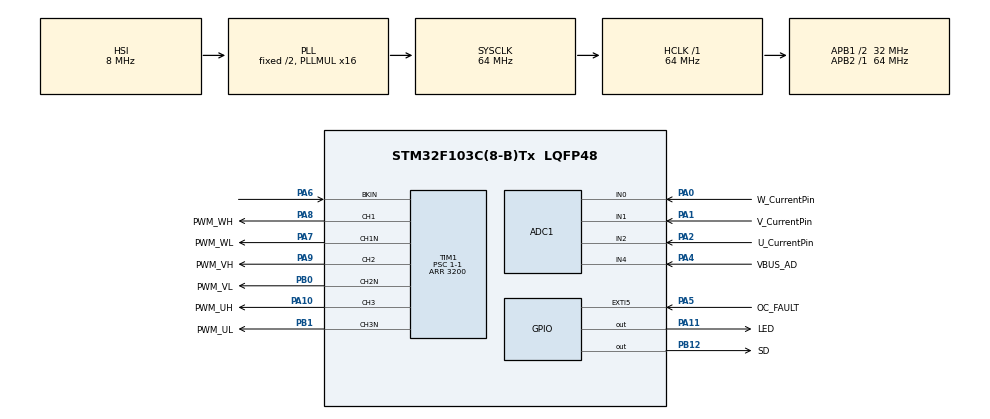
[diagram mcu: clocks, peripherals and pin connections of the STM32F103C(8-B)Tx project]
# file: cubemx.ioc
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ADC1.Channel-3\#ChannelInjectedConversion=ADC_CHANNEL_2
ADC1.Channel-4\#ChannelInjectedConversion=ADC_CHANNEL_1
ADC1.Channel-5\#ChannelInjectedConversion=ADC_CHANNEL_0
ADC1.Channel-6\#ChannelInjectedConversion=ADC_CHANNEL_0
ADC1.Channel-7\#ChannelRegularConversion=ADC_CHANNEL_4
ADC1.DataAlign=ADC_DATAALIGN_RIGHT
ADC1.EnableInjectedConversion=ENABLE
ADC1.EnableRegularConversion=ENABLE
ADC1.ExternalTrigInjecConv=ADC_EXTERNALTRIGINJECCONV_T1_CC4
ADC1.InjNumberOfConversion=3
ADC1.InjectedConvMode=None
ADC1.InjectedOffset-3\#ChannelInjectedConversion=0
ADC1.InjectedOffset-4\#ChannelInjectedConversion=0
ADC1.InjectedOffset-5\#ChannelInjectedConversion=0
ADC1.InjectedOffset-6\#ChannelInjectedConversion=0
ADC1.NbrOfConversionFlag=1
ADC1.Rank-3\#ChannelInjectedConversion=1
ADC1.Rank-4\#ChannelInjectedConversion=2
ADC1.Rank-5\#ChannelInjectedConversion=3
ADC1.Rank-6\#ChannelInjectedConversion=4
ADC1.Rank-7\#ChannelRegularConversion=1
ADC1.SamplingTime-3\#ChannelInjectedConversion=ADC_SAMPLETIME_7CYCLES_5
ADC1.SamplingTime-4\#ChannelInjectedConversion=ADC_SAMPLETIME_7CYCLES_5
ADC1.SamplingTime-5\#ChannelInjectedConversion=ADC_SAMPLETIME_7CYCLES_5
ADC1.SamplingTime-6\#ChannelInjectedConversion=ADC_SAMPLETIME_1CYCLE_5
ADC1.SamplingTime-7\#ChannelRegularConversion=ADC_SAMPLETIME_41CYCLES_5
ADC1.master=1
Mcu.Family=STM32F1
Mcu.Name=STM32F103C(8-B)Tx
Mcu.Package=LQFP48
NVIC.ADC1_2_IRQn=true\:0\:0\:false\:false\:true\:true\:true\:true
NVIC.EXTI9_5_IRQn=true\:0\:0\:false\:false\:true\:true\:true\:true
NVIC.PriorityGroup=NVIC_PRIORITYGROUP_2
NVIC.TIM1_BRK_IRQn=true\:0\:0\:false\:false\:true\:true\:true\:true
NVIC.TIM1_UP_IRQn=true\:0\:0\:false\:false\:true\:true\:true\:true
NVIC.TIM2_IRQn=true\:1\:0\:true\:false\:true\:true\:true\:true
PA0-WKUP.GPIO_Label=W_CurrentPin
PA0-WKUP.Signal=ADCx_IN0
PA1.GPIO_Label=V_CurrentPin
PA1.Signal=ADCx_IN1
PA10.GPIO_Label=PWM_UH
PA10.GPIO_Speed=GPIO_SPEED_FREQ_HIGH
PA10.Signal=S_TIM1_CH3
PA11.GPIO_Label=LED
PA11.Signal=GPIO_Output
PA13.GPIO_Label=SWDIO
PA13.Mode=Serial_Wire
PA13.Signal=SYS_JTMS-SWDIO
PA14.GPIO_Label=SWCLK
PA14.Mode=Serial_Wire
PA14.Signal=SYS_JTCK-SWCLK
PA2.GPIO_Label=U_CurrentPin
PA2.Signal=ADCx_IN2
PA4.GPIO_Label=VBUS_AD
PA4.Signal=ADCx_IN4
PA5.GPIO_Label=OC_FAULT
PA5.GPIO_ModeDefaultEXTI=GPIO_MODE_IT_FALLING
PA5.GPIO_PuPd=GPIO_PULLUP
PA5.Signal=GPXTI5
PA6.Mode=Activate-Break-Input
PA6.Signal=TIM1_BKIN
PA7.GPIO_Label=PWM_WL
PA7.GPIO_Speed=GPIO_SPEED_FREQ_HIGH
PA7.Mode=PWM Generation1 CH1 CH1N
PA7.Signal=TIM1_CH1N
PA8.GPIO_Label=PWM_WH
PA8.GPIO_Speed=GPIO_SPEED_FREQ_HIGH
PA8.Signal=S_TIM1_CH1
PA9.GPIO_Label=PWM_VH
PA9.GPIO_Speed=GPIO_SPEED_FREQ_HIGH
PA9.Signal=S_TIM1_CH2
PB0.GPIO_Label=PWM_VL
PB0.GPIO_Speed=GPIO_SPEED_FREQ_HIGH
PB0.Mode=PWM Generation2 CH2 CH2N
PB0.Signal=TIM1_CH2N
PB1.GPIO_Label=PWM_UL
PB1.GPIO_Speed=GPIO_SPEED_FREQ_HIGH
PB1.Mode=PWM Generation3 CH3 CH3N
PB1.Signal=TIM1_CH3N
PB12.GPIO_Label=SD
PB12.Signal=GPIO_Output
ProjectManager.HeapSize=0x200
ProjectManager.StackSize=0x400
ProjectManager.TargetToolchain=MDK-ARM V5.27
RCC.ADCPresc=RCC_ADCPCLK2_DIV6
RCC.AHBFreq_Value=64000000
RCC.APB1CLKDivider=RCC_HCLK_DIV2
RCC.APB1Freq_Value=32000000
RCC.APB1TimFreq_Value=64000000
RCC.APB2Freq_Value=64000000
RCC.APB2TimFreq_Value=64000000
RCC.HCLKFreq_Value=64000000
RCC.PLLMUL=RCC_PLL_MUL16
RCC.SYSCLKFreq_VALUE=64000000
RCC.SYSCLKSource=RCC_SYSCLKSOURCE_PLLCLK
RCC.USBFreq_Value=64000000
SH.ADCx_IN0.0=ADC1_IN0,IN0
SH.ADCx_IN1.0=ADC1_IN1,IN1
SH.ADCx_IN2.0=ADC1_IN2,IN2
SH.ADCx_IN4.0=ADC1_IN4,IN4
SH.S_TIM1_CH1.0=TIM1_CH1,PWM Generation1 CH1 CH1N
SH.S_TIM1_CH2.0=TIM1_CH2,PWM Generation2 CH2 CH2N
SH.S_TIM1_CH3.0=TIM1_CH3,PWM Generation3 CH3 CH3N
TIM1.BreakPolarity=TIM_BREAKPOLARITY_LOW
TIM1.Channel-PWM\ Generation1\ CH1\ CH1N=TIM_CHANNEL_1
TIM1.Channel-PWM\ Generation2\ CH2\ CH2N=TIM_CHANNEL_2
TIM1.Channel-PWM\ Generation3\ CH3\ CH3N=TIM_CHANNEL_3
TIM1.Channel-PWM\ Generation4\ No\ Output=TIM_CHANNEL_4
TIM1.ClockDivision=TIM_CLOCKDIVISION_DIV2
TIM1.CounterMode=TIM_COUNTERMODE_CENTERALIGNED1
TIM1.DeadTime=10
TIM1.LockLevel=TIM_LOCKLEVEL_1
TIM1.OCMode_PWM-PWM\ Generation4\ No\ Output=TIM_OCMODE_PWM2
TIM1.OffStateIDLEMode=TIM_OSSI_ENABLE
TIM1.OffStateRunMode=TIM_OSSR_ENABLE
TIM1.Period=3200
TIM1.Prescaler=1-1
TIM1.RepetitionCounter=1
TIM1.TIM_MasterOutputTrigger=TIM_TRGO_RESET
TIM1.TIM_MasterSlaveMode=TIM_MASTERSLAVEMODE_DISABLE
TIM2.AutoReloadPreload=TIM_AUTORELOAD_PRELOAD_ENABLE
TIM2.Period=1000-1
TIM2.Prescaler=64-1
VP_TIM1_VS_ClockSourceINT.Mode=Internal
VP_TIM1_VS_ClockSourceITR.Mode=TriggerSource_ITR1
VP_TIM1_VS_ControllerModeTrigger.Mode=Trigger Mode
VP_TIM1_VS_no_output4.Mode=PWM Generation4 No Output
VP_TIM2_VS_ClockSourceINT.Mode=Internal
board=custom

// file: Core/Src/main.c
/* USER CODE BEGIN Header */
/**
  ******************************************************************************
  * @file           : main.c
  * @brief          : Main program body
  ******************************************************************************
  * @attention
  *
  * Copyright (c) 2026 STMicroelectronics.
  * All rights reserved.
  *
  * This software is licensed under terms that can be found in the LICENSE file
  * in the root directory of this software component.
  * If no LICENSE file comes with this software, it is provided AS-IS.
  *
  ******************************************************************************
  */
/* USER CODE END Header */
#include "main.h"
#include "adc.h"
#include "tim.h"
#include "gpio.h"

/* USER CODE BEGIN Includes */
#include    "Ramdef.h"
#include    "pid.h"
#include    "pll.h"
#include    "smo.h"
/* USER CODE END Includes */

/* USER CODE BEGIN PV */
Timer_Data  unTimerData;
DebugData   unDebug;
PID_Handle  PID_Debug;
/* USER CODE END PV */

void SystemClock_Config(void);

int main(void)
{

  /* MCU Configuration--------------------------------------------------------*/

  /* Reset of all peripherals, Initializes the Flash interface and the Systick. */
  HAL_Init();

  /* Configure the system clock */
  SystemClock_Config();

  /* Initialize all configured peripherals */
  MX_GPIO_Init();
  MX_ADC1_Init();
  MX_TIM1_Init();
  MX_TIM2_Init();
  /* USER CODE BEGIN 2 */
	HAL_TIM_Base_Start_IT(&htim2);
  /* USER CODE END 2 */

  /* Infinite loop */
  while (1)
  {

    /* USER CODE BEGIN 3 */
//      PLL_Test();
      SMO_Test_Run();
  }
  /* USER CODE END 3 */
}

void SystemClock_Config(void)
{
  RCC_OscInitTypeDef RCC_OscInitStruct = {0};
  RCC_ClkInitTypeDef RCC_ClkInitStruct = {0};
  RCC_PeriphCLKInitTypeDef PeriphClkInit = {0};

  /** Initializes the RCC Oscillators according to the specified parameters
  * in the RCC_OscInitTypeDef structure.
  */
  RCC_OscInitStruct.OscillatorType = RCC_OSCILLATORTYPE_HSI;
  RCC_OscInitStruct.HSIState = RCC_HSI_ON;
  RCC_OscInitStruct.HSICalibrationValue = RCC_HSICALIBRATION_DEFAULT;
  RCC_OscInitStruct.PLL.PLLState = RCC_PLL_ON;
  RCC_OscInitStruct.PLL.PLLSource = RCC_PLLSOURCE_HSI_DIV2;
  RCC_OscInitStruct.PLL.PLLMUL = RCC_PLL_MUL16;
  if (HAL_RCC_OscConfig(&RCC_OscInitStruct) != HAL_OK)
  {
    Error_Handler();
  }

  /** Initializes the CPU, AHB and APB buses clocks
  */
  RCC_ClkInitStruct.ClockType = RCC_CLOCKTYPE_HCLK|RCC_CLOCKTYPE_SYSCLK
                              |RCC_CLOCKTYPE_PCLK1|RCC_CLOCKTYPE_PCLK2;
  RCC_ClkInitStruct.SYSCLKSource = RCC_SYSCLKSOURCE_PLLCLK;
  RCC_ClkInitStruct.AHBCLKDivider = RCC_SYSCLK_DIV1;
  RCC_ClkInitStruct.APB1CLKDivider = RCC_HCLK_DIV2;
  RCC_ClkInitStruct.APB2CLKDivider = RCC_HCLK_DIV1;

  if (HAL_RCC_ClockConfig(&RCC_ClkInitStruct, FLASH_LATENCY_2) != HAL_OK)
  {
    Error_Handler();
  }
  PeriphClkInit.PeriphClockSelection = RCC_PERIPHCLK_ADC;
  PeriphClkInit.AdcClockSelection = RCC_ADCPCLK2_DIV6;
  if (HAL_RCCEx_PeriphCLKConfig(&PeriphClkInit) != HAL_OK)
  {
    Error_Handler();
  }
}

void Error_Handler(void)
{
  __disable_irq();
  while (1)
  {
  }
}
